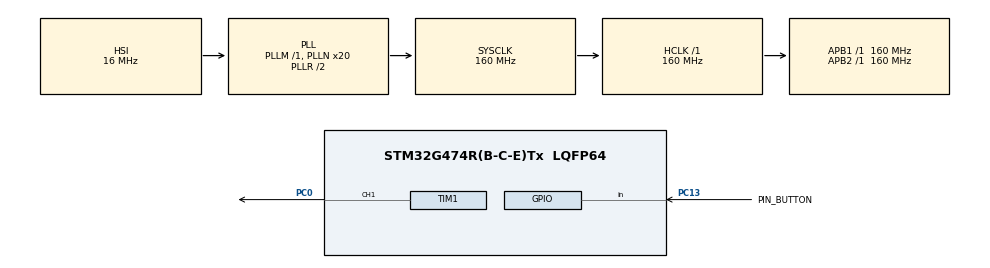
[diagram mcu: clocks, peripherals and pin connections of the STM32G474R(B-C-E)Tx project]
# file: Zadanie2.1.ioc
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Dma.Request0=TIM1_CH1
Dma.TIM1_CH1.0.Direction=DMA_MEMORY_TO_PERIPH
Dma.TIM1_CH1.0.EventEnable=DISABLE
Dma.TIM1_CH1.0.Instance=DMA1_Channel1
Dma.TIM1_CH1.0.MemDataAlignment=DMA_MDATAALIGN_HALFWORD
Dma.TIM1_CH1.0.MemInc=DMA_MINC_ENABLE
Dma.TIM1_CH1.0.Mode=DMA_NORMAL
Dma.TIM1_CH1.0.PeriphDataAlignment=DMA_PDATAALIGN_HALFWORD
Dma.TIM1_CH1.0.PeriphInc=DMA_PINC_DISABLE
Dma.TIM1_CH1.0.Polarity=HAL_DMAMUX_REQ_GEN_RISING
Dma.TIM1_CH1.0.Priority=DMA_PRIORITY_LOW
Dma.TIM1_CH1.0.RequestNumber=1
Dma.TIM1_CH1.0.SignalID=NONE
Dma.TIM1_CH1.0.SyncEnable=DISABLE
Dma.TIM1_CH1.0.SyncPolarity=HAL_DMAMUX_SYNC_NO_EVENT
Dma.TIM1_CH1.0.SyncRequestNumber=1
Dma.TIM1_CH1.0.SyncSignalID=NONE
Mcu.Family=STM32G4
Mcu.Name=STM32G474R(B-C-E)Tx
Mcu.Package=LQFP64
NVIC.DMA1_Channel1_IRQn=true\:0\:0\:false\:false\:true\:false\:true\:true
NVIC.PriorityGroup=NVIC_PRIORITYGROUP_4
PC0.Signal=S_TIM1_CH1
PC13.GPIO_Label=PIN_BUTTON
PC13.GPIO_PuPd=GPIO_PULLDOWN
PC13.Signal=GPIO_Input
ProjectManager.HeapSize=0x200
ProjectManager.StackSize=0x400
ProjectManager.TargetToolchain=CMake
RCC.ADC12Freq_Value=160000000
RCC.ADC345Freq_Value=160000000
RCC.AHBFreq_Value=160000000
RCC.APB1Freq_Value=160000000
RCC.APB1TimFreq_Value=160000000
RCC.APB2Freq_Value=160000000
RCC.APB2TimFreq_Value=160000000
RCC.CortexFreq_Value=160000000
RCC.EXTERNAL_CLOCK_VALUE=12288000
RCC.HCLKFreq_Value=160000000
RCC.HSE_VALUE=8000000
RCC.HSI48_VALUE=48000000
RCC.HSI_VALUE=16000000
RCC.LSE_VALUE=32768
RCC.PLLN=20
RCC.SYSCLKFreq_VALUE=160000000
RCC.SYSCLKSource=RCC_SYSCLKSOURCE_PLLCLK
RCC.USBFreq_Value=160000000
RCC.VCOOutputFreq_Value=320000000
SH.S_TIM1_CH1.0=TIM1_CH1,PWM Generation1 CH1
TIM1.Channel-PWM\ Generation1\ CH1=TIM_CHANNEL_1
TIM1.PeriodNoDither=200
VP_SYS_VS_DBSignals.Mode=DisableDeadBatterySignals
board=custom

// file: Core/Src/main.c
/* USER CODE BEGIN Header */
/**
  ******************************************************************************
  * @file           : main.c
  * @brief          : Main program body
  ******************************************************************************
  * @attention
  *
  * Copyright (c) 2025 STMicroelectronics.
  * All rights reserved.
  *
  * This software is licensed under terms that can be found in the LICENSE file
  * in the root directory of this software component.
  * If no LICENSE file comes with this software, it is provided AS-IS.
  *
  ******************************************************************************
  */
/* USER CODE END Header */
#include "main.h"

TIM_HandleTypeDef htim1;
DMA_HandleTypeDef hdma_tim1_ch1;

void SystemClock_Config(void);
static void MX_GPIO_Init(void);
static void MX_DMA_Init(void);
static void MX_TIM1_Init(void);

/* USER CODE BEGIN 0 */

const static uint8_t ledBrightnessCorrection8[] = {
    0,  0,  0,  0,  0,  0,  0,  0,  0,  0,  0,  0,  0,  0,  0,  0,
    0,  0,  0,  0,  0,  0,  0,  0,  0,  0,  0,  0,  1,  1,  1,  1,
    1,  1,  1,  1,  1,  1,  1,  1,  1,  2,  2,  2,  2,  2,  2,  2,
    2,  3,  3,  3,  3,  3,  3,  3,  4,  4,  4,  4,  4,  5,  5,  5,
    5,  6,  6,  6,  6,  7,  7,  7,  7,  8,  8,  8,  9,  9,  9, 10,
   10, 10, 11, 11, 11, 12, 12, 13, 13, 13, 14, 14, 15, 15, 16, 16,
   17, 17, 18, 18, 19, 19, 20, 20, 21, 21, 22, 22, 23, 24, 24, 25,
   25, 26, 27, 27, 28, 29, 29, 30, 31, 32, 32, 33, 34, 35, 35, 36,
   37, 38, 39, 39, 40, 41, 42, 43, 44, 45, 46, 47, 48, 49, 50, 50,
   51, 52, 54, 55, 56, 57, 58, 59, 60, 61, 62, 63, 64, 66, 67, 68,
   69, 70, 72, 73, 74, 75, 77, 78, 79, 81, 82, 83, 85, 86, 87, 89,
   90, 92, 93, 95, 96, 98, 99,101,102,104,105,107,109,110,112,114,
  115,117,119,120,122,124,126,127,129,131,133,135,137,138,140,142,
  144,146,148,150,152,154,156,158,160,162,164,167,169,171,173,175,
  177,180,182,184,186,189,191,193,196,198,200,203,205,208,210,213,
  215,218,220,223,225,228,231,233,236,239,241,244,247,249,252,255};

static uint16_t ledDma[24+50];
static uint8_t ledReadyForData = 1;

void HAL_TIM_PWM_PulseFinishedCallback(TIM_HandleTypeDef *htim)
{
	if (htim == &htim1)
		ledReadyForData = 1;
}

// Sends data to WS2812B
void SetLED(uint8_t green, uint8_t red, uint8_t blue)
{
	// encode rgb value to DMA buffer
	uint32_t data = (green << 16) | (red << 8) | blue;
	int dataIndex = 0;
	for (int i = 23; i >= 0; --i)
	{
		if(data & (1 << i)) ledDma[dataIndex] = 128; // 128 / 200 * 1.25us = 0.8us -> 1
		else ledDma[dataIndex] = 64; // 64 / 200 * 1.25us = 0.4us -> 0
		++dataIndex;
	}

	// transmission stop
	for (int i = 0; i < 50; ++i)
	{
		ledDma[dataIndex++] = 0;
	}

	HAL_TIM_PWM_Start_DMA(&htim1, TIM_CHANNEL_1, (uint32_t*)ledDma, 24+50);
	ledReadyForData = 0;
}

// Calculates LED color and sends data to WS2812B
void UpdateLED()
{
	if (!ledReadyForData) return;

	const uint32_t millis = HAL_GetTick();
	const uint32_t colorCycleInterval = 3000; // ms
	const uint32_t colorCycleIntervalHalf = colorCycleInterval / 2;
	static uint32_t lastButtonPressTime = INT32_MAX;
	const uint32_t timeSinceLastPress = millis - lastButtonPressTime;

	uint8_t red = ((millis / colorCycleIntervalHalf) % 2) * 255;
	uint8_t green = (millis % colorCycleInterval) * 255 / colorCycleInterval;
	uint8_t blue = 0;

	if (timeSinceLastPress >= colorCycleInterval * 3)
	{
		if (HAL_GPIO_ReadPin(PIN_BUTTON_GPIO_Port, PIN_BUTTON_Pin)) // button with pull down resistor
		{
			lastButtonPressTime = millis;
		}
	}
	else
	{
		blue = ((timeSinceLastPress % colorCycleInterval) < colorCycleIntervalHalf) * 255;
	}

	// Correct led brightness
	green = ledBrightnessCorrection8[green];
	//red = ledGammaCorrection8[red]; // not needed because it's only on or off
	//blue = ledGammaCorrection8[blue]; // not needed because it's only on or off

	SetLED(green, red, blue);
}
/* USER CODE END 0 */

int main(void)
{

  /* MCU Configuration--------------------------------------------------------*/

  /* Reset of all peripherals, Initializes the Flash interface and the Systick. */
  HAL_Init();

  /* Configure the system clock */
  SystemClock_Config();

  /* Initialize all configured peripherals */
  MX_GPIO_Init();
  MX_DMA_Init();
  MX_TIM1_Init();

  /* Infinite loop */
  /* USER CODE BEGIN WHILE */
  while (1)
  {
	  UpdateLED();
    /* USER CODE END WHILE */

  }
}

void SystemClock_Config(void)
{
  RCC_OscInitTypeDef RCC_OscInitStruct = {0};
  RCC_ClkInitTypeDef RCC_ClkInitStruct = {0};

  /** Configure the main internal regulator output voltage
  */
  HAL_PWREx_ControlVoltageScaling(PWR_REGULATOR_VOLTAGE_SCALE1_BOOST);

  /** Initializes the RCC Oscillators according to the specified parameters
  * in the RCC_OscInitTypeDef structure.
  */
  RCC_OscInitStruct.OscillatorType = RCC_OSCILLATORTYPE_HSI;
  RCC_OscInitStruct.HSIState = RCC_HSI_ON;
  RCC_OscInitStruct.HSICalibrationValue = RCC_HSICALIBRATION_DEFAULT;
  RCC_OscInitStruct.PLL.PLLState = RCC_PLL_ON;
  RCC_OscInitStruct.PLL.PLLSource = RCC_PLLSOURCE_HSI;
  RCC_OscInitStruct.PLL.PLLM = RCC_PLLM_DIV1;
  RCC_OscInitStruct.PLL.PLLN = 20;
  RCC_OscInitStruct.PLL.PLLP = RCC_PLLP_DIV2;
  RCC_OscInitStruct.PLL.PLLQ = RCC_PLLQ_DIV2;
  RCC_OscInitStruct.PLL.PLLR = RCC_PLLR_DIV2;
  if (HAL_RCC_OscConfig(&RCC_OscInitStruct) != HAL_OK)
  {
    Error_Handler();
  }

  /** Initializes the CPU, AHB and APB buses clocks
  */
  RCC_ClkInitStruct.ClockType = RCC_CLOCKTYPE_HCLK|RCC_CLOCKTYPE_SYSCLK
                              |RCC_CLOCKTYPE_PCLK1|RCC_CLOCKTYPE_PCLK2;
  RCC_ClkInitStruct.SYSCLKSource = RCC_SYSCLKSOURCE_PLLCLK;
  RCC_ClkInitStruct.AHBCLKDivider = RCC_SYSCLK_DIV1;
  RCC_ClkInitStruct.APB1CLKDivider = RCC_HCLK_DIV1;
  RCC_ClkInitStruct.APB2CLKDivider = RCC_HCLK_DIV1;

  if (HAL_RCC_ClockConfig(&RCC_ClkInitStruct, FLASH_LATENCY_4) != HAL_OK)
  {
    Error_Handler();
  }
}

static void MX_TIM1_Init(void)
{

  TIM_MasterConfigTypeDef sMasterConfig = {0};
  TIM_OC_InitTypeDef sConfigOC = {0};
  TIM_BreakDeadTimeConfigTypeDef sBreakDeadTimeConfig = {0};

  htim1.Instance = TIM1;
  htim1.Init.Prescaler = 0;
  htim1.Init.CounterMode = TIM_COUNTERMODE_UP;
  htim1.Init.Period = 200;
  htim1.Init.ClockDivision = TIM_CLOCKDIVISION_DIV1;
  htim1.Init.RepetitionCounter = 0;
  htim1.Init.AutoReloadPreload = TIM_AUTORELOAD_PRELOAD_DISABLE;
  if (HAL_TIM_PWM_Init(&htim1) != HAL_OK)
  {
    Error_Handler();
  }
  sMasterConfig.MasterOutputTrigger = TIM_TRGO_RESET;
  sMasterConfig.MasterOutputTrigger2 = TIM_TRGO2_RESET;
  sMasterConfig.MasterSlaveMode = TIM_MASTERSLAVEMODE_DISABLE;
  if (HAL_TIMEx_MasterConfigSynchronization(&htim1, &sMasterConfig) != HAL_OK)
  {
    Error_Handler();
  }
  sConfigOC.OCMode = TIM_OCMODE_PWM1;
  sConfigOC.Pulse = 0;
  sConfigOC.OCPolarity = TIM_OCPOLARITY_HIGH;
  sConfigOC.OCNPolarity = TIM_OCNPOLARITY_HIGH;
  sConfigOC.OCFastMode = TIM_OCFAST_DISABLE;
  sConfigOC.OCIdleState = TIM_OCIDLESTATE_RESET;
  sConfigOC.OCNIdleState = TIM_OCNIDLESTATE_RESET;
  if (HAL_TIM_PWM_ConfigChannel(&htim1, &sConfigOC, TIM_CHANNEL_1) != HAL_OK)
  {
    Error_Handler();
  }
  sBreakDeadTimeConfig.OffStateRunMode = TIM_OSSR_DISABLE;
  sBreakDeadTimeConfig.OffStateIDLEMode = TIM_OSSI_DISABLE;
  sBreakDeadTimeConfig.LockLevel = TIM_LOCKLEVEL_OFF;
  sBreakDeadTimeConfig.DeadTime = 0;
  sBreakDeadTimeConfig.BreakState = TIM_BREAK_DISABLE;
  sBreakDeadTimeConfig.BreakPolarity = TIM_BREAKPOLARITY_HIGH;
  sBreakDeadTimeConfig.BreakFilter = 0;
  sBreakDeadTimeConfig.BreakAFMode = TIM_BREAK_AFMODE_INPUT;
  sBreakDeadTimeConfig.Break2State = TIM_BREAK2_DISABLE;
  sBreakDeadTimeConfig.Break2Polarity = TIM_BREAK2POLARITY_HIGH;
  sBreakDeadTimeConfig.Break2Filter = 0;
  sBreakDeadTimeConfig.Break2AFMode = TIM_BREAK_AFMODE_INPUT;
  sBreakDeadTimeConfig.AutomaticOutput = TIM_AUTOMATICOUTPUT_DISABLE;
  if (HAL_TIMEx_ConfigBreakDeadTime(&htim1, &sBreakDeadTimeConfig) != HAL_OK)
  {
    Error_Handler();
  }
  HAL_TIM_MspPostInit(&htim1);

}

static void MX_DMA_Init(void)
{

  /* DMA controller clock enable */
  __HAL_RCC_DMAMUX1_CLK_ENABLE();
  __HAL_RCC_DMA1_CLK_ENABLE();

  /* DMA interrupt init */
  /* DMA1_Channel1_IRQn interrupt configuration */
  HAL_NVIC_SetPriority(DMA1_Channel1_IRQn, 0, 0);
  HAL_NVIC_EnableIRQ(DMA1_Channel1_IRQn);

}

static void MX_GPIO_Init(void)
{
  GPIO_InitTypeDef GPIO_InitStruct = {0};

  /* GPIO Ports Clock Enable */
  __HAL_RCC_GPIOC_CLK_ENABLE();

  /*Configure GPIO pin : PIN_BUTTON_Pin */
  GPIO_InitStruct.Pin = PIN_BUTTON_Pin;
  GPIO_InitStruct.Mode = GPIO_MODE_INPUT;
  GPIO_InitStruct.Pull = GPIO_PULLDOWN;
  HAL_GPIO_Init(PIN_BUTTON_GPIO_Port, &GPIO_InitStruct);

}

void Error_Handler(void)
{
  __disable_irq();
  while (1)
  {
  }
}
